VERSION ""

NS_ :

BS_:

BU_:

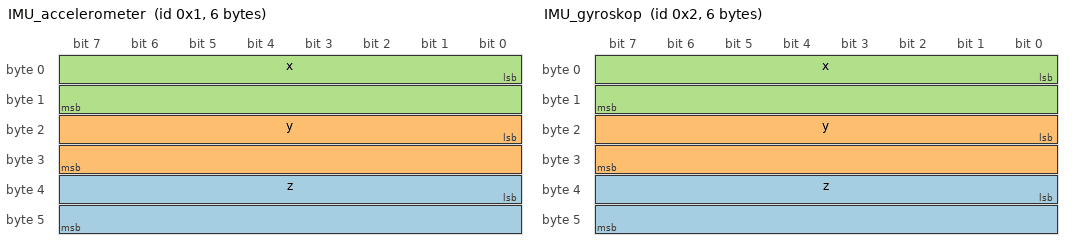
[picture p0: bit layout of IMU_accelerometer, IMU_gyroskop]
BO_ 1 IMU_accelerometer: 6 Vector__XXX
 SG_ z : 32|16@1- (1,0) [0|0] "" Vector__XXX
 SG_ y : 16|16@1- (1,0) [0|0] "" Vector__XXX
 SG_ x : 0|16@1- (1,0) [0|0] "" Vector__XXX

BO_ 2 IMU_gyroskop: 6 Vector__XXX
 SG_ z : 32|16@1- (1,0) [0|0] "" Vector__XXX
 SG_ y : 16|16@1- (1,0) [0|0] "" Vector__XXX
 SG_ x : 0|16@1- (1,0) [0|0] "" Vector__XXX

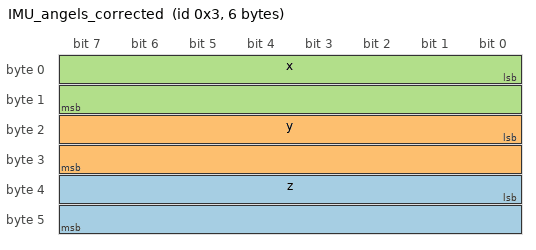
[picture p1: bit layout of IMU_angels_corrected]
BO_ 3 IMU_angels_corrected: 6 Vector__XXX
 SG_ z : 32|16@1- (1,0) [0|0] "" Vector__XXX
 SG_ y : 16|16@1- (1,0) [0|0] "" Vector__XXX
 SG_ x : 0|16@1- (1,0) [0|0] "" Vector__XXX

BA_DEF_  "BusType" STRING ;
BA_DEF_DEF_  "BusType" "CAN";
